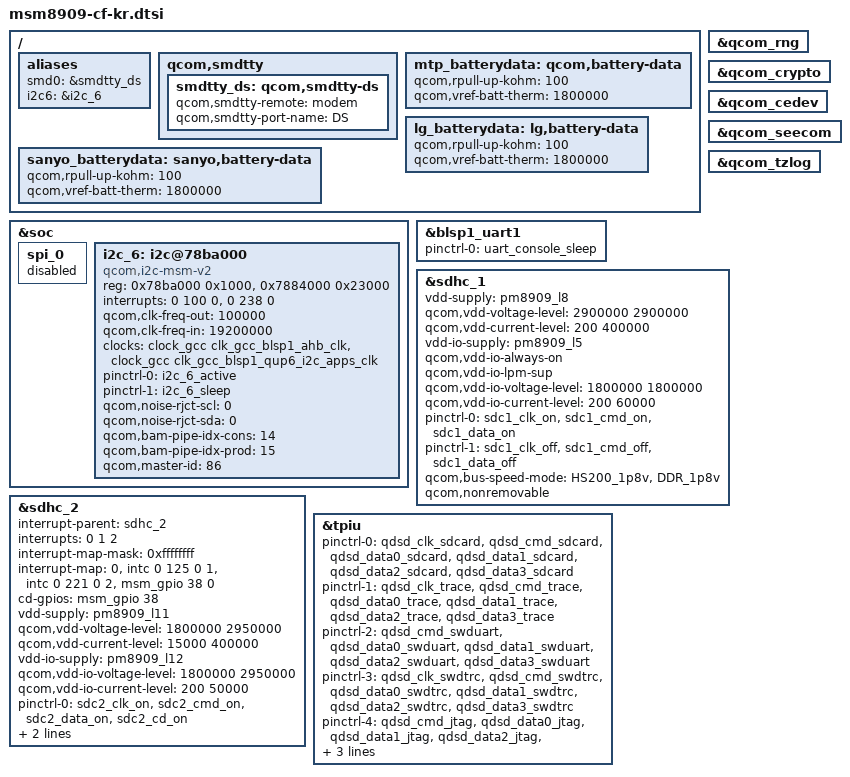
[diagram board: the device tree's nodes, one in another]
/* Copyright (c) 2014, The Linux Foundation. All rights reserved.
 *
 * This program is free software; you can redistribute it and/or modify
 * it under the terms of the GNU General Public License version 2 and
 * only version 2 as published by the Free Software Foundation.
 *
 * This program is distributed in the hope that it will be useful,
 * but WITHOUT ANY WARRANTY; without even the implied warranty of
 * MERCHANTABILITY or FITNESS FOR A PARTICULAR PURPOSE.  See the
 * GNU General Public License for more details.
 */

#include "../../qcom/msm8909.dtsi"
#include "../../qcom/msm8909-pinctrl.dtsi"
#include "../../qcom/msm8909-memory.dtsi"
#include "../msm8909-lge-common/msm8909-common.dtsi"
#include "msm8909-cf-kr-pinctrl.dtsi"
#include "msm8909-cf-kr-sensor.dtsi"

/ {
	aliases {
		smd0 = &smdtty_ds;
		i2c6 = &i2c_6; /* I2c6 cntroller device */
	};

	qcom,smdtty {
		smdtty_ds: qcom,smdtty-ds {
			qcom,smdtty-remote = "modem";
			qcom,smdtty-port-name = "DS";
		};
	};
};

&soc {
	spi_0 {
		status = "disabled";
	};

	i2c_6: i2c@78ba000 { /* BLSP1 QUP6 */
		compatible = "qcom,i2c-msm-v2";
		#address-cells = <1>;
		#size-cells = <0>;
		reg-names = "qup_phys_addr", "bam_phys_addr";
		reg = <0x78ba000 0x1000>,
		      <0x7884000 0x23000>;
		interrupt-names = "qup_irq", "bam_irq";
		interrupts = <0 100 0>, <0 238 0>;
		qcom,clk-freq-out = <100000>;
		qcom,clk-freq-in  = <19200000>;
		clock-names = "iface_clk", "core_clk";
		clocks = <&clock_gcc clk_gcc_blsp1_ahb_clk>,
			 <&clock_gcc clk_gcc_blsp1_qup6_i2c_apps_clk>;

		pinctrl-names = "i2c_active", "i2c_sleep";
		pinctrl-0 = <&i2c_6_active>;
		pinctrl-1 = <&i2c_6_sleep>;
		qcom,noise-rjct-scl = <0>;
		qcom,noise-rjct-sda = <0>;
		qcom,bam-pipe-idx-cons = <14>;
		qcom,bam-pipe-idx-prod = <15>;
		qcom,master-id = <86>;
	};
};

&blsp1_uart1 {
	status = "ok";
	pinctrl-names = "default";
	pinctrl-0 = <&uart_console_sleep>;
};

/ {
	mtp_batterydata: qcom,battery-data {
		qcom,rpull-up-kohm = <100>;
		qcom,vref-batt-therm = <1800000>;

		#include "../../qcom/batterydata-palladium.dtsi"
	};
};
/ {
	lg_batterydata: lg,battery-data {
		qcom,rpull-up-kohm = <100>;
		qcom,vref-batt-therm = <1800000>;

		#include "../msm8909-lge-common/batterydata-lgc-1700mah.dtsi"
	};
};
/ {
	sanyo_batterydata: sanyo,battery-data {
		qcom,rpull-up-kohm = <100>;
		qcom,vref-batt-therm = <1800000>;

		#include "../msm8909-lge-common/batterydata-sanyo-1700mah.dtsi"
	};
};
&qcom_rng {
	status = "okay";
};

&qcom_crypto {
	status = "okay";
};

&qcom_cedev {
	status = "okay";
};

&qcom_seecom {
	status = "okay";
};

&qcom_tzlog {
	status = "okay";
};

&sdhc_1 {
	vdd-supply = <&pm8909_l8>;
	qcom,vdd-voltage-level = <2900000 2900000>;
	qcom,vdd-current-level = <200 400000>;

	vdd-io-supply = <&pm8909_l5>;
	qcom,vdd-io-always-on;
	qcom,vdd-io-lpm-sup;
	qcom,vdd-io-voltage-level = <1800000 1800000>;
	qcom,vdd-io-current-level = <200 60000>;

	pinctrl-names = "active", "sleep";
	pinctrl-0 = <&sdc1_clk_on &sdc1_cmd_on &sdc1_data_on>;
	pinctrl-1 = <&sdc1_clk_off &sdc1_cmd_off &sdc1_data_off>;

	qcom,bus-speed-mode = "HS200_1p8v", "DDR_1p8v";
	qcom,nonremovable;

	status = "ok";
};

&sdhc_2 {
	 #address-cells = <0>;
	interrupt-parent = <&sdhc_2>;
	interrupts = <0 1 2>;
	#interrupt-cells = <1>;
	interrupt-map-mask = <0xffffffff>;
	interrupt-map = <0 &intc 0 125 0
			1 &intc 0 221 0
			2 &msm_gpio 38 0>;
	interrupt-names = "hc_irq", "pwr_irq", "status_irq";
	cd-gpios = <&msm_gpio 38 0x0>;

	vdd-supply = <&pm8909_l11>;
	qcom,vdd-voltage-level = <1800000 2950000>;
	qcom,vdd-current-level = <15000 400000>;

	vdd-io-supply = <&pm8909_l12>;
	qcom,vdd-io-voltage-level = <1800000 2950000>;
	qcom,vdd-io-current-level = <200 50000>;

	pinctrl-names = "active", "sleep";
	pinctrl-0 = <&sdc2_clk_on &sdc2_cmd_on &sdc2_data_on &sdc2_cd_on>;
	pinctrl-1 = <&sdc2_clk_off &sdc2_cmd_off &sdc2_data_off &sdc2_cd_off>;

	status = "ok";
};

/* CoreSight */
&tpiu {
	pinctrl-names = "sdcard", "trace", "swduart",
			"swdtrc", "jtag", "spmi";
	/* NIDnT */
	pinctrl-0 = <&qdsd_clk_sdcard &qdsd_cmd_sdcard
		     &qdsd_data0_sdcard &qdsd_data1_sdcard
		     &qdsd_data2_sdcard &qdsd_data3_sdcard>;
	pinctrl-1 = <&qdsd_clk_trace &qdsd_cmd_trace
		     &qdsd_data0_trace &qdsd_data1_trace
		     &qdsd_data2_trace &qdsd_data3_trace>;
	pinctrl-2 = <&qdsd_cmd_swduart &qdsd_data0_swduart
		     &qdsd_data1_swduart &qdsd_data2_swduart
		     &qdsd_data3_swduart>;
	pinctrl-3 = <&qdsd_clk_swdtrc &qdsd_cmd_swdtrc
		     &qdsd_data0_swdtrc &qdsd_data1_swdtrc
		     &qdsd_data2_swdtrc &qdsd_data3_swdtrc>;
	pinctrl-4 = <&qdsd_cmd_jtag &qdsd_data0_jtag
		     &qdsd_data1_jtag &qdsd_data2_jtag
		     &qdsd_data3_jtag>;
	pinctrl-5 = <&qdsd_clk_spmi &qdsd_cmd_spmi
		     &qdsd_data0_spmi &qdsd_data3_spmi>;
};

#include "msm8909-cf-kr-pm.dtsi"
#include "msm8909-cf-kr-usb.dtsi"
#include "msm8909-cf-kr-misc.dtsi"
#include "msm8909-cf-kr-sound.dtsi"
#include "msm8909-cf-kr-camera.dtsi"
#include "msm8909-cf-kr-panel.dtsi"
#include "msm8909-cf-kr-tdmb.dtsi"
